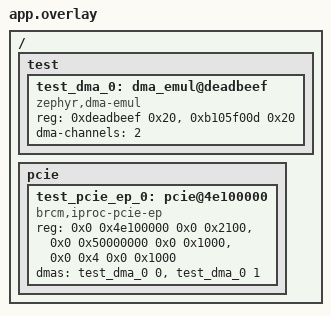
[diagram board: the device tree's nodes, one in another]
/*
 * Copyright (c) 2020, Linaro Ltd.
 *
 * SPDX-License-Identifier: Apache-2.0
 *
 * Application overlay for testing driver builds
 *
 * Names in this file should be chosen in a way that won't conflict
 * with real-world devicetree nodes, to allow these tests to run on
 * (and be extended to test) real hardware.
 */

/ {
	test {
		#address-cells = <1>;
		#size-cells = <1>;

		test_dma_0: dma_emul@deadbeef {
			#dma-cells = <1>;

			compatible = "zephyr,dma-emul";
			reg = <0xdeadbeef 0x20>,
			      <0xb105f00d 0x20>;
			reg-names = "foo_regs",
				    "bar_regs";
			dma-channels = <2>;
			status = "okay";
		};
	};

	pcie {
		#address-cells = <2>;
		#size-cells = <2>;

		test_pcie_ep_0: pcie@4e100000 {
			compatible = "brcm,iproc-pcie-ep";
			reg = <0x0 0x4e100000 0x0 0x2100>,
			      <0x0 0x50000000 0x0 0x1000>,
			      <0x0 0x4 0x0 0x1000>;
			reg-names = "iproc_pcie_regs", "map_lowmem",
				    "map_highmem";
			dmas = <&test_dma_0 0>, <&test_dma_0 1>;
			dma-names = "txdma", "rxdma";
			status = "okay";
		};

/*
		test_pcie_ep_1: pcie@4e200000 {
			compatible = "brcm,iproc-pcie-ep";
			reg = <0x0 0x4e200000 0x0 0x2100>,
			      <0x0 0x60000000 0x0 0x1000>,
			      <0x4 0x0 0x0 0x1000>;
			reg-names = "iproc_pcie_regs", "map_lowmem",
				    "map_highmem";
			dmas = <&test_dma_0 0>, <&test_dma_0 1>;
			dma-names = "txdma", "rxdma";
		};
*/
	};
};
